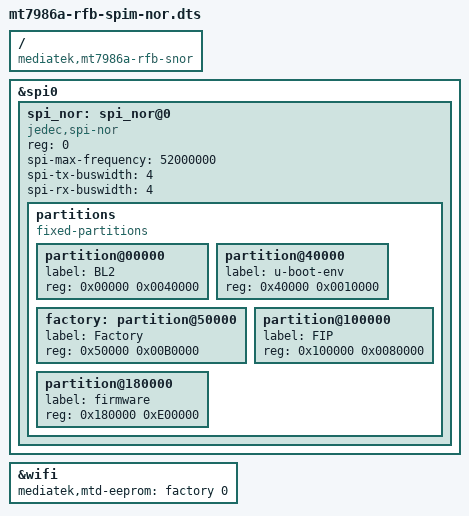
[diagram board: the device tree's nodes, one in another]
/* SPDX-License-Identifier: (GPL-2.0-only OR MIT) */

#include "mt7986a-rfb.dtsi"

/ {
	compatible = "mediatek,mt7986a-rfb-snor";
};

&spi0 {
	status = "okay";

	spi_nor: spi_nor@0 {
		#address-cells = <1>;
		#size-cells = <1>;
		compatible = "jedec,spi-nor";
		reg = <0>;
		spi-max-frequency = <52000000>;
		spi-tx-buswidth = <4>;
		spi-rx-buswidth = <4>;
		partitions {
			compatible = "fixed-partitions";
			#address-cells = <1>;
			#size-cells = <1>;

			partition@00000 {
				label = "BL2";
				reg = <0x00000 0x0040000>;
			};
			partition@40000 {
				label = "u-boot-env";
				reg = <0x40000 0x0010000>;
			};
			factory: partition@50000 {
				label = "Factory";
				reg = <0x50000 0x00B0000>;
			};
			partition@100000 {
				label = "FIP";
				reg = <0x100000 0x0080000>;
			};
			partition@180000 {
				label = "firmware";
				reg = <0x180000 0xE00000>;
			};
		};
	};
};

&wifi {
	mediatek,mtd-eeprom = <&factory 0>;
};
